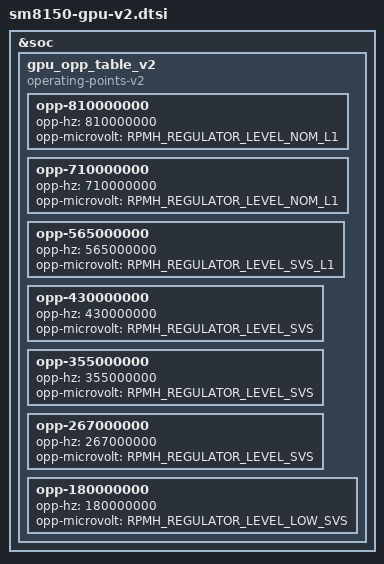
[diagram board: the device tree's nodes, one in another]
/* Copyright (c) 2018-2019, The Linux Foundation. All rights reserved.
 *
 * This program is free software; you can redistribute it and/or modify
 * it under the terms of the GNU General Public License version 2 and
 * only version 2 as published by the Free Software Foundation.
 *
 * This program is distributed in the hope that it will be useful,
 * but WITHOUT ANY WARRANTY; without even the implied warranty of
 * MERCHANTABILITY or FITNESS FOR A PARTICULAR PURPOSE.  See the
 * GNU General Public License for more details.
 */

&soc {
	gpu_opp_table_v2: gpu_opp_table_v2 {
		compatible = "operating-points-v2";

		opp-810000000 {
			opp-hz = /bits/ 64 <810000000>;
			opp-microvolt = <RPMH_REGULATOR_LEVEL_NOM_L1>;
		};

		opp-710000000 {
			opp-hz = /bits/ 64 <710000000>;
			opp-microvolt = <RPMH_REGULATOR_LEVEL_NOM_L1>;
		};

		opp-565000000 {
			opp-hz = /bits/ 64 <565000000>;
			opp-microvolt = <RPMH_REGULATOR_LEVEL_SVS_L1>;
		};

		opp-430000000 {
			opp-hz = /bits/ 64 <430000000>;
			opp-microvolt = <RPMH_REGULATOR_LEVEL_SVS>;
		};

		opp-355000000 {
			opp-hz = /bits/ 64 <355000000>;
			opp-microvolt = <RPMH_REGULATOR_LEVEL_SVS>;
		};

		opp-267000000 {
			opp-hz = /bits/ 64 <267000000>;
			opp-microvolt = <RPMH_REGULATOR_LEVEL_SVS>;
		};

		opp-180000000 {
			opp-hz = /bits/ 64 <180000000>;
			opp-microvolt = <RPMH_REGULATOR_LEVEL_LOW_SVS>;
		};
	};
};
